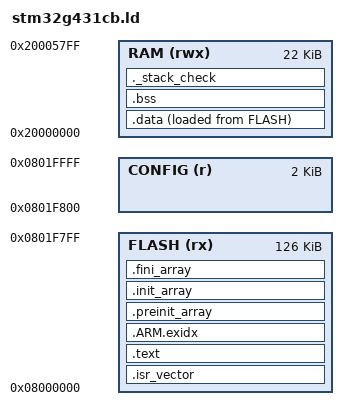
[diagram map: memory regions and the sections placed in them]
/* STM32G431CB: 128 KB flash (last 2 KB page = config), 22 KB SRAM1+SRAM2 */
ENTRY(Reset_Handler)

MEMORY
{
  FLASH (rx)  : ORIGIN = 0x08000000, LENGTH = 126K
  CONFIG (r)  : ORIGIN = 0x0801F800, LENGTH = 2K
  RAM (rwx)   : ORIGIN = 0x20000000, LENGTH = 22K
}

_estack = ORIGIN(RAM) + LENGTH(RAM);
_Min_Stack = 0x800;

SECTIONS
{
  .isr_vector : { KEEP(*(.isr_vector)) } > FLASH

  .text :
  {
    *(.text*)
    *(.rodata*)
    KEEP(*(.init))
    KEEP(*(.fini))
    . = ALIGN(4);
  } > FLASH

  .ARM.exidx : { *(.ARM.exidx* .gnu.linkonce.armexidx.*) } > FLASH

  .preinit_array : { PROVIDE_HIDDEN(__preinit_array_start = .); KEEP(*(.preinit_array*)); PROVIDE_HIDDEN(__preinit_array_end = .); } > FLASH
  .init_array :    { PROVIDE_HIDDEN(__init_array_start = .); KEEP(*(SORT(.init_array.*))); KEEP(*(.init_array*)); PROVIDE_HIDDEN(__init_array_end = .); } > FLASH
  .fini_array :    { PROVIDE_HIDDEN(__fini_array_start = .); KEEP(*(SORT(.fini_array.*))); KEEP(*(.fini_array*)); PROVIDE_HIDDEN(__fini_array_end = .); } > FLASH

  _sidata = LOADADDR(.data);
  .data :
  {
    . = ALIGN(4);
    _sdata = .;
    *(.data*)
    . = ALIGN(4);
    _edata = .;
  } > RAM AT > FLASH

  .bss (NOLOAD) :
  {
    . = ALIGN(4);
    _sbss = .;
    *(.bss*)
    *(COMMON)
    . = ALIGN(4);
    _ebss = .;
    end = .;
    _end = .;
  } > RAM

  ._stack_check (NOLOAD) : { . = . + _Min_Stack; } > RAM
}
